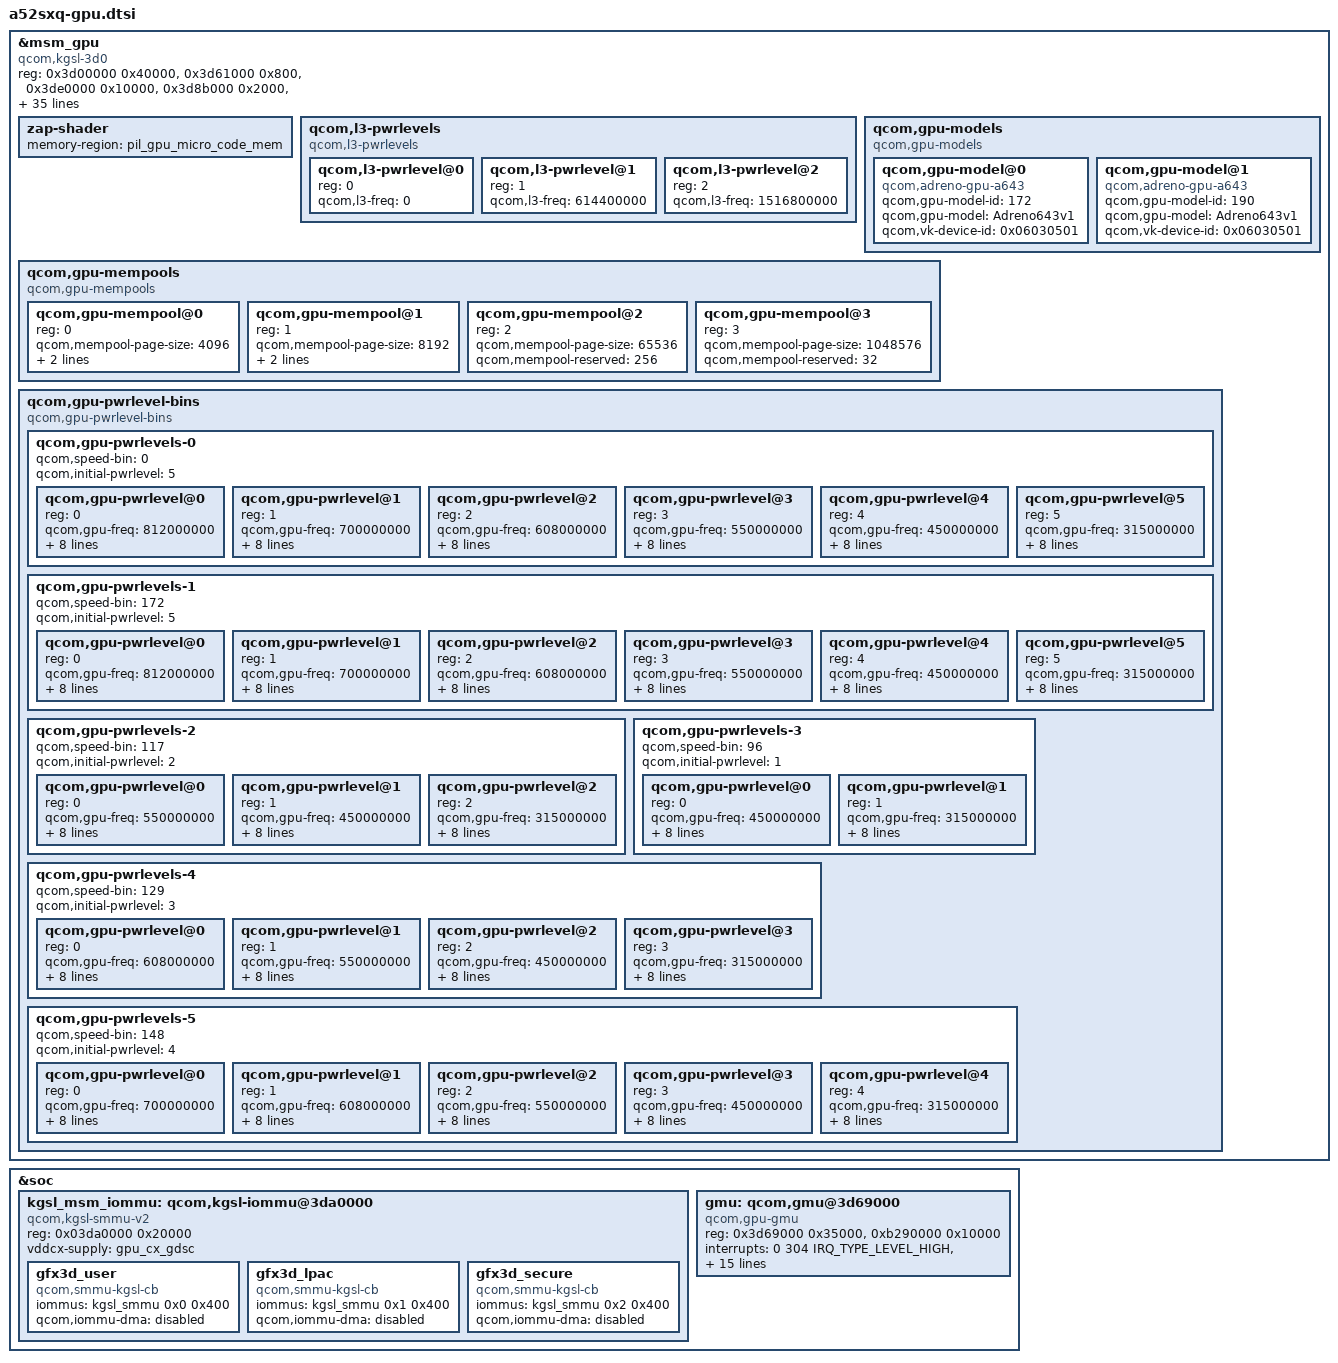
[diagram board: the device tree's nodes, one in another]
// SPDX-License-Identifier: BSD-3-Clause
/*
 * Samsung Galaxy A52s 5G (a52sxq, SM7325 yupik): Adreno 642L / KGSL for Qualcomm's 6.12 base
 * (bsp612/out/dist/dtb/yupik.dtb, downstream 6.12 bindings).
 *
 * WHY THE WHOLE GPU IS HERE: the 6.12 yupik base only has an empty stub
 *     msm_gpu: qcom,kgsl-3d0@3d00000 { #cooling-cells = <2>; };
 * (Qualcomm ships the GPU nodes in a separate graphics-devicetree project). No GMU node, no
 * qcom,kgsl-iommu node, no power levels. Present in the base and reused here: kgsl_smmu
 * (qcom,adreno-smmu @3da0000), gpucc, gpu_cx_gdsc, gpu_gx_gdsc, the qfprom cells
 * gpu_speed_bin/gpu_gaming_bin/gpu_model_bin, pil_gpu_micro_code_mem, thermal zones gpuss-0/1
 * with gpu_cdev cooling maps that already point at &msm_gpu.
 *
 * SOURCE OF VALUES: structure = Qualcomm's 6.12 yupik-gpu.dtsi + yupik-gpu-pwrlevels.dtsi (as
 * carried by the redwood-6.12 SM7325 port); every number was then compared with the node the
 * phone boots on 5.4 (downstream-dt/a52sxq-r02.dts) by ./dt-verify.sh: registers, interrupt,
 * clocks, chipid, bus tables, all 5 speed bins / power levels / ACD levels, mempools, iommu
 * SIDs, GMU, zap memory region are identical. Samsung does not override anything inside the
 * GPU node (revisions r00..r04 all take Qualcomm's yupik-gpu.dtsi unchanged; the Samsung
 * overlay only adds cooling maps that reference &msm_gpu: pm8350c-bcl-lvl1/vph_gpu,
 * pm7325_tz/pm7325_gpu, pm8350c_tz/pm8350c_gpu -> thermal fragment, not here).
 *
 * DELIBERATE DIFFERENCES from the phone's 5.4 node (all forced by the 6.12 driver/bindings):
 *  - zap shader: 5.4 used a PIL node (pil_gpu: qcom,kgsl-hyp, qcom,pil-tz-generic,
 *    firmware "a660_zap", pas-id 13). The 6.12 driver loads "a660_zap.mdt" itself with
 *    qcom_mdt_load()+qcom_scm_pas_auth_and_reset(13) and wants a "zap-shader" child with
 *    memory-region. Same reserved region (gpu_micro_code@8b71a000, 0x2000). Userspace-visible
 *    change: /dev/subsys_a660_zap and /sys/class/subsys/subsys_a660_zap do not exist any more.
 *  - apb_pclk: <&aoss_qmp> (6.12 QDSS clock provider) instead of <&aopcc QDSS_CLK>.
 *  - qcom,tzone-names: the 6.12 base names the zones "gpuss-0"/"gpuss-1" (5.4: "gpuss-0-usr",
 *    "gpuss-1-usr").
 *  - dropped, the 6.12 driver does not parse them: qcom,no-nap, the "l3_path" interconnect
 *    (base has no epss_l3_cpu provider), qcom,kgsl-ddr-qos (qcom,devfreq-qoslat is gone).
 *    qcom,l3-pwrlevels is kept for reference (ignored).
 *  - GMU reg: 0x3d69000+0x35000 (Qualcomm 6.12) instead of 0x3d6a000+0x34000 (5.4). The 6.12
 *    driver addresses GMU registers through a regmap keyed on the resource start, so the larger
 *    window is a superset. If GMU register reads fault on hardware, try the 5.4 window.
 *
 * Needs: dt-bindings gcc-sc7280, gpucc-sc7280, interconnect qcom,yupik, arm-gic,
 * rpmh-regulator-levels (all already included by yupik.dtsi). ./dt-verify.sh also writes a
 * preprocessed, literal-number copy (out/a52sxq-gpu.pp.dtso) for a plain-dtc overlay build.
 */

#define MHZ_TO_KBPS(mhz, w) ((mhz * 1000000 * w) / (1024))

&msm_gpu {
	compatible = "qcom,kgsl-3d0", "qcom,adreno-gpu-a642l";
	status = "ok";

	reg = <0x3d00000 0x40000>, <0x3d61000 0x800>,
		<0x3de0000 0x10000>, <0x3d8b000 0x2000>,
		<0x06900000 0x80000>, <0x0636000 0x1000>,
		<0x3d9e000 0x1000>;

	reg-names = "kgsl_3d0_reg_memory", "cx_dbgc", "rscc",
		"isense_cntl", "qdss_gfx", "rdpm_mx",
		"cx_misc";

	interrupts = <0 300 IRQ_TYPE_LEVEL_HIGH>;
	interrupt-names = "kgsl_3d0_irq";

	clocks = <&gcc GCC_GPU_MEMNOC_GFX_CLK>,
		<&gcc GCC_GPU_SNOC_DVM_GFX_CLK>,
		<&gpucc GPU_CC_AHB_CLK>,
		<&aoss_qmp>,
		<&gpucc GPU_CC_HLOS1_VOTE_GPU_SMMU_CLK>,
		<&gpucc GPU_CC_CX_GMU_CLK>,
		<&gpucc GPU_CC_HUB_AON_CLK>,
		<&gpucc GPU_CC_HUB_CX_INT_CLK>;

	clock-names = "gcc_gpu_memnoc_gfx",
			"gcc_gpu_snoc_dvm_gfx",
			"gpu_cc_ahb",
			"apb_pclk",
			"gpu_cc_hlos1_vote_gpu_smmu",
			"gpu_cc_cx_gmu",
			"gpu_cc_hub_aon",
			"gpu_cc_hub_cx_int";

	qcom,chipid = <0x06030500>;
	qcom,gpu-model = "Adreno642Lv1";

	qcom,min-access-length = <32>;
	qcom,ubwc-mode = <3>;

	nvmem-cells = <&gpu_speed_bin>, <&gpu_gaming_bin>, <&gpu_model_bin>;
	nvmem-cell-names = "speed_bin", "gaming_bin", "gpu_model";

	qcom,tzone-names = "gpuss-0", "gpuss-1";

	interconnects = <&gem_noc MASTER_GFX3D &mc_virt SLAVE_EBI1>;
	interconnect-names = "gpu_icc_path";

	qcom,bus-table-ddr7 =
		<MHZ_TO_KBPS(0, 4)>,    /* index=0 */
		<MHZ_TO_KBPS(200, 4)>,  /* index=1,  LOW_SVS  */
		<MHZ_TO_KBPS(451, 4)>,  /* index=2,  LOW_SVS  */
		<MHZ_TO_KBPS(547, 4)>,  /* index=3,  LOW_SVS  */
		<MHZ_TO_KBPS(681, 4)>,  /* index=4,  SVS  */
		<MHZ_TO_KBPS(768, 4)>,  /* index=5,  SVS  */
		<MHZ_TO_KBPS(1017, 4)>, /* index=6,  SVS  */
		<MHZ_TO_KBPS(1353, 4)>, /* index=7,  NOM  */
		<MHZ_TO_KBPS(1555, 4)>, /* index=8,  NOM  */
		<MHZ_TO_KBPS(1708, 4)>, /* index=9,  NOM  */
		<MHZ_TO_KBPS(2092, 4)>, /* index=10, TURBO  */
		<MHZ_TO_KBPS(2133, 4)>; /* index=11, TURBO */

	qcom,bus-table-ddr8 =
		<MHZ_TO_KBPS(0, 4)>,    /* index=0 */
		<MHZ_TO_KBPS(200, 4)>,  /* index=1,  LOW_SVS */
		<MHZ_TO_KBPS(451, 4)>,  /* index=2,  LOW_SVS  */
		<MHZ_TO_KBPS(547, 4)>,  /* index=3,  LOW_SVS  */
		<MHZ_TO_KBPS(681, 4)>,  /* index=4,  SVS */
		<MHZ_TO_KBPS(768, 4)>,  /* index=5,  SVS  */
		<MHZ_TO_KBPS(1555, 4)>, /* index=6,  SVS  */
		<MHZ_TO_KBPS(1708, 4)>, /* index=7,  SVS_L1  */
		<MHZ_TO_KBPS(2092, 4)>, /* index=8,  NOM  */
		<MHZ_TO_KBPS(2736, 4)>, /* index=9, TURBO_L1  */
		<MHZ_TO_KBPS(3196, 4)>; /* index=10, TURBO_L1  */

	qcom,bus-table-cnoc =
		<0>,   /* Off */
		<100>; /* On */

	zap-shader {
		memory-region = <&pil_gpu_micro_code_mem>;
	};

	qcom,l3-pwrlevels {
		#address-cells = <1>;
		#size-cells = <0>;

		compatible = "qcom,l3-pwrlevels";

		qcom,l3-pwrlevel@0 {
			reg = <0>;
			qcom,l3-freq = <0>;
		};

		qcom,l3-pwrlevel@1 {
			reg = <1>;
			qcom,l3-freq = <614400000>;
		};

		qcom,l3-pwrlevel@2 {
			reg = <2>;
			qcom,l3-freq = <1516800000>;
		};
	};

	qcom,gpu-models {
		#address-cells = <1>;
		#size-cells = <0>;
		compatible="qcom,gpu-models";

		qcom,gpu-model@0 {
			compatible="qcom,adreno-gpu-a643";
			qcom,gpu-model-id = <172>;
			qcom,gpu-model = "Adreno643v1";
			qcom,vk-device-id = <0x06030501>;
		};

		qcom,gpu-model@1 {
			compatible="qcom,adreno-gpu-a643";
			qcom,gpu-model-id = <190>;
			qcom,gpu-model = "Adreno643v1";
			qcom,vk-device-id = <0x06030501>;
		};
	};

	qcom,gpu-mempools {
		#address-cells = <1>;
		#size-cells = <0>;
		compatible = "qcom,gpu-mempools";

		/* 4K Page Pool configuration */
		qcom,gpu-mempool@0 {
			reg = <0>;
			qcom,mempool-page-size = <4096>;
			qcom,mempool-reserved = <2048>;
			qcom,mempool-allocate;
		};
			/* 8K Page Pool configuration */
		qcom,gpu-mempool@1 {
			reg = <1>;
			qcom,mempool-page-size = <8192>;
			qcom,mempool-reserved = <1024>;
			qcom,mempool-allocate;
		};
		/* 64K Page Pool configuration */
		qcom,gpu-mempool@2 {
			reg = <2>;
			qcom,mempool-page-size = <65536>;
			qcom,mempool-reserved = <256>;
		};
		/* 1M Page Pool configuration */
		qcom,gpu-mempool@3 {
			reg = <3>;
			qcom,mempool-page-size = <1048576>;
			qcom,mempool-reserved = <32>;
		};
	};
};

&soc {
	kgsl_msm_iommu: qcom,kgsl-iommu@3da0000 {
		compatible = "qcom,kgsl-smmu-v2";
		reg = <0x03da0000 0x20000>;

		vddcx-supply = <&gpu_cx_gdsc>;

		gfx3d_user: gfx3d_user {
			compatible = "qcom,smmu-kgsl-cb";
			iommus = <&kgsl_smmu 0x0 0x400>;
			qcom,iommu-dma = "disabled";
		};

		gfx3d_lpac: gfx3d_lpac {
			compatible = "qcom,smmu-kgsl-cb";
			iommus = <&kgsl_smmu 0x1 0x400>;
			qcom,iommu-dma = "disabled";
		};

		gfx3d_secure: gfx3d_secure {
			compatible = "qcom,smmu-kgsl-cb";
			iommus = <&kgsl_smmu 0x2 0x400>;
			qcom,iommu-dma = "disabled";
		};
	};

	gmu: qcom,gmu@3d69000 {
		compatible = "qcom,gpu-gmu";

		reg = <0x3d69000 0x35000>,
			<0xb290000 0x10000>;

		reg-names = "kgsl_gmu_reg",
			"kgsl_gmu_pdc_cfg";

		interrupts = <0 304 IRQ_TYPE_LEVEL_HIGH>,
			<0 305 IRQ_TYPE_LEVEL_HIGH>;
		interrupt-names = "kgsl_hfi_irq", "kgsl_gmu_irq";

		regulator-names = "vddcx", "vdd";

		iommus = <&kgsl_smmu 0x5 0x400>;
		qcom,iommu-dma = "disabled";

		vddcx-supply = <&gpu_cx_gdsc>;
		vdd-supply = <&gpu_gx_gdsc>;

		clocks = <&gpucc GPU_CC_CX_GMU_CLK>,
			<&gpucc GPU_CC_CXO_CLK>,
			<&gcc GCC_DDRSS_GPU_AXI_CLK>,
			<&gcc GCC_GPU_MEMNOC_GFX_CLK>,
			<&gpucc GPU_CC_AHB_CLK>,
			<&gpucc GPU_CC_HUB_CX_INT_CLK>,
			<&gpucc GPU_CC_HLOS1_VOTE_GPU_SMMU_CLK>;

		clock-names = "gmu_clk", "cxo_clk", "axi_clk",
			"memnoc_clk", "ahb_clk", "hub_clk", "smmu_vote";

		mboxes = <&qmp_aop 0>;
		mbox-names = "aop";
	};
};

&msm_gpu {
	qcom,gpu-pwrlevel-bins {
		#address-cells = <1>;
		#size-cells = <0>;

		compatible = "qcom,gpu-pwrlevel-bins";

		qcom,gpu-pwrlevels-0 {
			#address-cells = <1>;
			#size-cells = <0>;

			qcom,speed-bin = <0>;
			qcom,initial-pwrlevel = <5>;

			qcom,gpu-pwrlevel@0 {
				reg = <0>;
				qcom,gpu-freq = <812000000>;
				qcom,level = <RPMH_REGULATOR_LEVEL_NOM_L1>;

				qcom,bus-freq-ddr7 = <11>;
				qcom,bus-min-ddr7 = <11>;
				qcom,bus-max-ddr7 = <11>;

				qcom,bus-freq-ddr8 = <10>;
				qcom,bus-min-ddr8 = <9>;
				qcom,bus-max-ddr8 = <10>;

				qcom,acd-level = <0x802B5FFD>;
			};

			qcom,gpu-pwrlevel@1 {
				reg = <1>;
				qcom,gpu-freq = <700000000>;
				qcom,level = <RPMH_REGULATOR_LEVEL_NOM>;

				qcom,bus-freq-ddr7 = <11>;
				qcom,bus-min-ddr7 = <10>;
				qcom,bus-max-ddr7 = <11>;

				qcom,bus-freq-ddr8 = <9>;
				qcom,bus-min-ddr8 = <8>;
				qcom,bus-max-ddr8 = <10>;

				qcom,acd-level = <0x802B5FFD>;
			};

			qcom,gpu-pwrlevel@2 {
				reg = <2>;
				qcom,gpu-freq = <608000000>;
				qcom,level = <RPMH_REGULATOR_LEVEL_SVS_L2>;

				qcom,bus-freq-ddr7 = <10>;
				qcom,bus-min-ddr7 = <9>;
				qcom,bus-max-ddr7 = <11>;

				qcom,bus-freq-ddr8 = <8>;
				qcom,bus-min-ddr8 = <7>;
				qcom,bus-max-ddr8 = <10>;

				qcom,acd-level = <0x802B5FFD>;
			};

			qcom,gpu-pwrlevel@3 {
				reg = <3>;
				qcom,gpu-freq = <550000000>;
				qcom,level = <RPMH_REGULATOR_LEVEL_SVS_L1>;

				qcom,bus-freq-ddr7 = <9>;
				qcom,bus-min-ddr7 = <8>;
				qcom,bus-max-ddr7 = <11>;

				qcom,bus-freq-ddr8 = <7>;
				qcom,bus-min-ddr8 = <6>;
				qcom,bus-max-ddr8 = <9>;

				qcom,acd-level = <0x802B5FFD>;
			};

			qcom,gpu-pwrlevel@4 {
				reg = <4>;
				qcom,gpu-freq = <450000000>;
				qcom,level = <RPMH_REGULATOR_LEVEL_SVS>;

				qcom,bus-freq-ddr7 = <6>;
				qcom,bus-min-ddr7 = <5>;
				qcom,bus-max-ddr7 = <10>;

				qcom,bus-freq-ddr8 = <6>;
				qcom,bus-min-ddr8 = <6>;
				qcom,bus-max-ddr8 = <8>;

				qcom,acd-level = <0x802B5FFD>;
			};

			qcom,gpu-pwrlevel@5 {
				reg = <5>;
				qcom,gpu-freq = <315000000>;
				qcom,level = <RPMH_REGULATOR_LEVEL_LOW_SVS>;

				qcom,bus-freq-ddr7 = <3>;
				qcom,bus-min-ddr7 = <2>;
				qcom,bus-max-ddr7 = <9>;

				qcom,bus-freq-ddr8 = <3>;
				qcom,bus-min-ddr8 = <2>;
				qcom,bus-max-ddr8 = <7>;

				qcom,acd-level = <0x882F5FFD>;
			};
		};

		qcom,gpu-pwrlevels-1 {
			#address-cells = <1>;
			#size-cells = <0>;

			/* Keeping speed bin for FMAX 812 */
			qcom,speed-bin = <172>;
			qcom,initial-pwrlevel = <5>;

			qcom,gpu-pwrlevel@0 {
				reg = <0>;
				qcom,gpu-freq = <812000000>;
				qcom,level = <RPMH_REGULATOR_LEVEL_NOM_L1>;

				qcom,bus-freq-ddr7 = <11>;
				qcom,bus-min-ddr7 = <11>;
				qcom,bus-max-ddr7 = <11>;

				qcom,bus-freq-ddr8 = <10>;
				qcom,bus-min-ddr8 = <9>;
				qcom,bus-max-ddr8 = <10>;

				qcom,acd-level = <0x802B5FFD>;
			};

			qcom,gpu-pwrlevel@1 {
				reg = <1>;
				qcom,gpu-freq = <700000000>;
				qcom,level = <RPMH_REGULATOR_LEVEL_NOM>;

				qcom,bus-freq-ddr7 = <11>;
				qcom,bus-min-ddr7 = <10>;
				qcom,bus-max-ddr7 = <11>;

				qcom,bus-freq-ddr8 = <9>;
				qcom,bus-min-ddr8 = <8>;
				qcom,bus-max-ddr8 = <10>;

				qcom,acd-level = <0x802B5FFD>;
			};

			qcom,gpu-pwrlevel@2 {
				reg = <2>;
				qcom,gpu-freq = <608000000>;
				qcom,level = <RPMH_REGULATOR_LEVEL_SVS_L2>;

				qcom,bus-freq-ddr7 = <10>;
				qcom,bus-min-ddr7 = <9>;
				qcom,bus-max-ddr7 = <11>;

				qcom,bus-freq-ddr8 = <8>;
				qcom,bus-min-ddr8 = <7>;
				qcom,bus-max-ddr8 = <10>;

				qcom,acd-level = <0x802B5FFD>;
			};

			qcom,gpu-pwrlevel@3 {
				reg = <3>;
				qcom,gpu-freq = <550000000>;
				qcom,level = <RPMH_REGULATOR_LEVEL_SVS_L1>;

				qcom,bus-freq-ddr7 = <9>;
				qcom,bus-min-ddr7 = <8>;
				qcom,bus-max-ddr7 = <11>;

				qcom,bus-freq-ddr8 = <7>;
				qcom,bus-min-ddr8 = <6>;
				qcom,bus-max-ddr8 = <9>;

				qcom,acd-level = <0x802B5FFD>;
			};

			qcom,gpu-pwrlevel@4 {
				reg = <4>;
				qcom,gpu-freq = <450000000>;
				qcom,level = <RPMH_REGULATOR_LEVEL_SVS>;

				qcom,bus-freq-ddr7 = <6>;
				qcom,bus-min-ddr7 = <5>;
				qcom,bus-max-ddr7 = <10>;

				qcom,bus-freq-ddr8 = <6>;
				qcom,bus-min-ddr8 = <6>;
				qcom,bus-max-ddr8 = <8>;

				qcom,acd-level = <0x802B5FFD>;
			};

			qcom,gpu-pwrlevel@5 {
				reg = <5>;
				qcom,gpu-freq = <315000000>;
				qcom,level = <RPMH_REGULATOR_LEVEL_LOW_SVS>;

				qcom,bus-freq-ddr7 = <3>;
				qcom,bus-min-ddr7 = <2>;
				qcom,bus-max-ddr7 = <9>;

				qcom,bus-freq-ddr8 = <3>;
				qcom,bus-min-ddr8 = <2>;
				qcom,bus-max-ddr8 = <7>;

				qcom,acd-level = <0x882F5FFD>;
			};
		};

		qcom,gpu-pwrlevels-2 {
			#address-cells = <1>;
			#size-cells = <0>;

			qcom,speed-bin = <117>;
			qcom,initial-pwrlevel = <2>;

			qcom,gpu-pwrlevel@0 {
				reg = <0>;
				qcom,gpu-freq = <550000000>;
				qcom,level = <RPMH_REGULATOR_LEVEL_SVS_L1>;

				qcom,bus-freq-ddr7 = <9>;
				qcom,bus-min-ddr7 = <8>;
				qcom,bus-max-ddr7 = <11>;

				qcom,bus-freq-ddr8 = <7>;
				qcom,bus-min-ddr8 = <6>;
				qcom,bus-max-ddr8 = <9>;

				qcom,acd-level = <0x802B5FFD>;
			};

			qcom,gpu-pwrlevel@1 {
				reg = <1>;
				qcom,gpu-freq = <450000000>;
				qcom,level = <RPMH_REGULATOR_LEVEL_SVS>;

				qcom,bus-freq-ddr7 = <6>;
				qcom,bus-min-ddr7 = <5>;
				qcom,bus-max-ddr7 = <10>;

				qcom,bus-freq-ddr8 = <6>;
				qcom,bus-min-ddr8 = <6>;
				qcom,bus-max-ddr8 = <8>;

				qcom,acd-level = <0x802B5FFD>;
			};

			qcom,gpu-pwrlevel@2 {
				reg = <2>;
				qcom,gpu-freq = <315000000>;
				qcom,level = <RPMH_REGULATOR_LEVEL_LOW_SVS>;

				qcom,bus-freq-ddr7 = <3>;
				qcom,bus-min-ddr7 = <2>;
				qcom,bus-max-ddr7 = <9>;

				qcom,bus-freq-ddr8 = <3>;
				qcom,bus-min-ddr8 = <2>;
				qcom,bus-max-ddr8 = <7>;

				qcom,acd-level = <0x882F5FFD>;
			};
		};

		qcom,gpu-pwrlevels-3 {
			#address-cells = <1>;
			#size-cells = <0>;

			qcom,speed-bin = <96>;
			qcom,initial-pwrlevel = <1>;

			qcom,gpu-pwrlevel@0 {
				reg = <0>;
				qcom,gpu-freq = <450000000>;
				qcom,level = <RPMH_REGULATOR_LEVEL_SVS>;

				qcom,bus-freq-ddr7 = <6>;
				qcom,bus-min-ddr7 = <5>;
				qcom,bus-max-ddr7 = <10>;

				qcom,bus-freq-ddr8 = <6>;
				qcom,bus-min-ddr8 = <6>;
				qcom,bus-max-ddr8 = <8>;

				qcom,acd-level = <0x802B5FFD>;
			};

			qcom,gpu-pwrlevel@1 {
				reg = <1>;
				qcom,gpu-freq = <315000000>;
				qcom,level = <RPMH_REGULATOR_LEVEL_LOW_SVS>;

				qcom,bus-freq-ddr7 = <3>;
				qcom,bus-min-ddr7 = <2>;
				qcom,bus-max-ddr7 = <9>;

				qcom,bus-freq-ddr8 = <3>;
				qcom,bus-min-ddr8 = <2>;
				qcom,bus-max-ddr8 = <7>;

				qcom,acd-level = <0x882F5FFD>;
			};
		};

		qcom,gpu-pwrlevels-4 {
			#address-cells = <1>;
			#size-cells = <0>;

			qcom,speed-bin = <129>;
			qcom,initial-pwrlevel = <3>;

			qcom,gpu-pwrlevel@0 {
				reg = <0>;
				qcom,gpu-freq = <608000000>;
				qcom,level = <RPMH_REGULATOR_LEVEL_SVS_L2>;

				qcom,bus-freq-ddr7 = <10>;
				qcom,bus-min-ddr7 = <9>;
				qcom,bus-max-ddr7 = <11>;

				qcom,bus-freq-ddr8 = <8>;
				qcom,bus-min-ddr8 = <7>;
				qcom,bus-max-ddr8 = <10>;

				qcom,acd-level = <0x802B5FFD>;
			};

			qcom,gpu-pwrlevel@1 {
				reg = <1>;
				qcom,gpu-freq = <550000000>;
				qcom,level = <RPMH_REGULATOR_LEVEL_SVS_L1>;

				qcom,bus-freq-ddr7 = <9>;
				qcom,bus-min-ddr7 = <8>;
				qcom,bus-max-ddr7 = <11>;

				qcom,bus-freq-ddr8 = <7>;
				qcom,bus-min-ddr8 = <6>;
				qcom,bus-max-ddr8 = <9>;

				qcom,acd-level = <0x802B5FFD>;
			};

			qcom,gpu-pwrlevel@2 {
				reg = <2>;
				qcom,gpu-freq = <450000000>;
				qcom,level = <RPMH_REGULATOR_LEVEL_SVS>;

				qcom,bus-freq-ddr7 = <6>;
				qcom,bus-min-ddr7 = <5>;
				qcom,bus-max-ddr7 = <10>;

				qcom,bus-freq-ddr8 = <6>;
				qcom,bus-min-ddr8 = <6>;
				qcom,bus-max-ddr8 = <8>;

				qcom,acd-level = <0x802B5FFD>;
			};

			qcom,gpu-pwrlevel@3 {
				reg = <3>;
				qcom,gpu-freq = <315000000>;
				qcom,level = <RPMH_REGULATOR_LEVEL_LOW_SVS>;

				qcom,bus-freq-ddr7 = <3>;
				qcom,bus-min-ddr7 = <2>;
				qcom,bus-max-ddr7 = <9>;

				qcom,bus-freq-ddr8 = <3>;
				qcom,bus-min-ddr8 = <2>;
				qcom,bus-max-ddr8 = <7>;

				qcom,acd-level = <0x882F5FFD>;
			};
		};

		qcom,gpu-pwrlevels-5 {
			#address-cells = <1>;
			#size-cells = <0>;

			qcom,speed-bin = <148>;
			qcom,initial-pwrlevel = <4>;

			qcom,gpu-pwrlevel@0 {
				reg = <0>;
				qcom,gpu-freq = <700000000>;
				qcom,level = <RPMH_REGULATOR_LEVEL_NOM>;

				qcom,bus-freq-ddr7 = <11>;
				qcom,bus-min-ddr7 = <10>;
				qcom,bus-max-ddr7 = <11>;

				qcom,bus-freq-ddr8 = <9>;
				qcom,bus-min-ddr8 = <8>;
				qcom,bus-max-ddr8 = <10>;

				qcom,acd-level = <0x802B5FFD>;
			};

			qcom,gpu-pwrlevel@1 {
				reg = <1>;
				qcom,gpu-freq = <608000000>;
				qcom,level = <RPMH_REGULATOR_LEVEL_SVS_L2>;

				qcom,bus-freq-ddr7 = <10>;
				qcom,bus-min-ddr7 = <9>;
				qcom,bus-max-ddr7 = <11>;

				qcom,bus-freq-ddr8 = <8>;
				qcom,bus-min-ddr8 = <7>;
				qcom,bus-max-ddr8 = <10>;

				qcom,acd-level = <0x802B5FFD>;
			};

			qcom,gpu-pwrlevel@2 {
				reg = <2>;
				qcom,gpu-freq = <550000000>;
				qcom,level = <RPMH_REGULATOR_LEVEL_SVS_L1>;

				qcom,bus-freq-ddr7 = <9>;
				qcom,bus-min-ddr7 = <8>;
				qcom,bus-max-ddr7 = <11>;

				qcom,bus-freq-ddr8 = <7>;
				qcom,bus-min-ddr8 = <6>;
				qcom,bus-max-ddr8 = <9>;

				qcom,acd-level = <0x802B5FFD>;
			};

			qcom,gpu-pwrlevel@3 {
				reg = <3>;
				qcom,gpu-freq = <450000000>;
				qcom,level = <RPMH_REGULATOR_LEVEL_SVS>;

				qcom,bus-freq-ddr7 = <6>;
				qcom,bus-min-ddr7 = <5>;
				qcom,bus-max-ddr7 = <10>;

				qcom,bus-freq-ddr8 = <6>;
				qcom,bus-min-ddr8 = <6>;
				qcom,bus-max-ddr8 = <8>;

				qcom,acd-level = <0x802B5FFD>;
			};

			qcom,gpu-pwrlevel@4 {
				reg = <4>;
				qcom,gpu-freq = <315000000>;
				qcom,level = <RPMH_REGULATOR_LEVEL_LOW_SVS>;

				qcom,bus-freq-ddr7 = <3>;
				qcom,bus-min-ddr7 = <2>;
				qcom,bus-max-ddr7 = <9>;

				qcom,bus-freq-ddr8 = <3>;
				qcom,bus-min-ddr8 = <2>;
				qcom,bus-max-ddr8 = <7>;

				qcom,acd-level = <0x882F5FFD>;
			};
		};
	};
};
